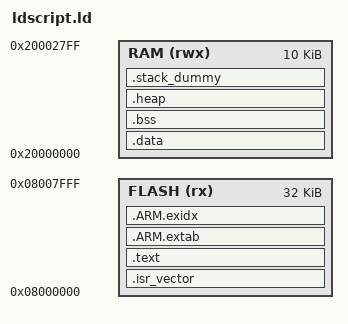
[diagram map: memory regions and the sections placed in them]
/*
 * STM32F407ZET6 ARM GCC linker script file, Martin Kojtal (0xc0170), Michal Chovanec
 */

MEMORY
{
    FLASH (rx)      : ORIGIN = 0x08000000, LENGTH = 32K
    RAM (rwx)       : ORIGIN = 0x20000000, LENGTH = 10K
} 

/* Highest address of the user mode stack */
//_estack = 0x20002000;
_estack = 0x20002800; 

/* Linker script to place sections and symbol values. Should be used together
 * with other linker script that defines memory regions FLASH and RAM.
 * It references following symbols, which must be defined in code:
 * _reset_init : Entry of reset handler
 *
 * It defines following symbols, which code can use without definition:
 * __exidx_start
 * __exidx_end
 * __etext
 * __data_start__
 * __preinit_array_start
 * __preinit_array_end
 * __init_array_start
 * __init_array_end
 * __fini_array_start
 * __fini_array_end
 * __data_end__
 * __bss_start__
 * __bss_end__
 * __end__
 * end
 * __HeapLimit
 * __StackLimit
 * __StackTop
 * __stack
 */
ENTRY(_reset_init)

SECTIONS
{
    .isr_vector :
    {
        __vector_table = .;
        KEEP(*(.isr_vector))
         . = ALIGN(4);
    } > FLASH


    .text :
    {
        *(.text*)

        KEEP(*(.init))
        KEEP(*(.fini))

        /* .ctors */
        *crtbegin.o(.ctors)
        *crtbegin?.o(.ctors)
        *(EXCLUDE_FILE(*crtend?.o *crtend.o) .ctors)
        *(SORT(.ctors.*))
        *(.ctors)

        /* .dtors */
        *crtbegin.o(.dtors)
        *crtbegin?.o(.dtors)
        *(EXCLUDE_FILE(*crtend?.o *crtend.o) .dtors)
        *(SORT(.dtors.*))
        *(.dtors)

        *(.rodata*)

        KEEP(*(.eh_frame*))
    } > FLASH

    .ARM.extab :
    {
        *(.ARM.extab* .gnu.linkonce.armextab.*)
    } > FLASH

    __exidx_start = .;
    .ARM.exidx :
    {
        *(.ARM.exidx* .gnu.linkonce.armexidx.*)
    } > FLASH
    __exidx_end = .;

    __etext = .;

    .data : AT (__etext)
    {
        __data_start__ = .;
        *(vtable)
        *(.data*)

        . = ALIGN(4);
        /* preinit data */
        PROVIDE_HIDDEN (__preinit_array_start = .);
        KEEP(*(.preinit_array))
        PROVIDE_HIDDEN (__preinit_array_end = .);



        . = ALIGN(4);
        /* All data end */
        __data_end__ = .;

    } > RAM

    .bss :
    {
        __bss_start__ = .;
        *(.bss*)
        *(COMMON)
        __bss_end__ = .;
    } > RAM

    .heap :
    {
        __end__ = .;
        end = __end__;
        *(.heap*)
        __HeapLimit = .;
    } > RAM

    /* .stack_dummy section doesn't contains any symbols. It is only
     * used for linker to calculate size of stack sections, and assign
     * values to stack symbols later */
    .stack_dummy :
    {
        *(.stack)
    } > RAM

    /* Set stack top to end of RAM, and stack limit move down by
     * size of stack_dummy section */
    __StackTop = ORIGIN(RAM) + LENGTH(RAM);
    __StackLimit = __StackTop - SIZEOF(.stack_dummy);
    PROVIDE(__stack = __StackTop);

    /* Check if data + heap + stack exceeds RAM limit */
    ASSERT(__StackLimit >= __HeapLimit, "region RAM overflowed with stack")
}
